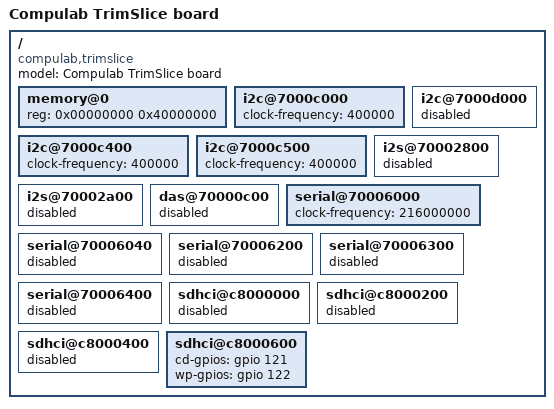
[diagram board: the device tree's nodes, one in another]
/*
 * arch/arm/boot/dts/tegra20-trimslice.dts
 *
 * Copyright (C) 2012-2014 NVIDIA Corporation. All rights reserved.
 *
 * This software is licensed under the terms of the GNU General Public
 * License version 2, as published by the Free Software Foundation, and
 * may be copied, distributed, and modified under those terms.
 *
 * This program is distributed in the hope that it will be useful,
 * but WITHOUT ANY WARRANTY; without even the implied warranty of
 * MERCHANTABILITY or FITNESS FOR A PARTICULAR PURPOSE.  See the
 * GNU General Public License for more details.
 *
 */

/dts-v1/;

/include/ "tegra20.dtsi"

/ {
	model = "Compulab TrimSlice board";
	compatible = "compulab,trimslice", "nvidia,tegra20";

	memory@0 {
		reg = < 0x00000000 0x40000000 >;
	};

	i2c@7000c000 {
		clock-frequency = <400000>;
	};

	i2c@7000c400 {
		clock-frequency = <400000>;
	};

	i2c@7000c500 {
		clock-frequency = <400000>;
	};

	i2c@7000d000 {
		status = "disable";
	};

	i2s@70002800 {
		status = "disable";
	};

	i2s@70002a00 {
		status = "disable";
	};

	das@70000c00 {
		status = "disable";
	};

	serial@70006000 {
		clock-frequency = < 216000000 >;
	};

	serial@70006040 {
		status = "disable";
	};

	serial@70006200 {
		status = "disable";
	};

	serial@70006300 {
		status = "disable";
	};

	serial@70006400 {
		status = "disable";
	};

	sdhci@c8000000 {
		status = "disable";
	};

	sdhci@c8000200 {
		status = "disable";
	};

	sdhci@c8000400 {
		status = "disable";
	};

	sdhci@c8000600 {
		cd-gpios = <&gpio 121 0>;
		wp-gpios = <&gpio 122 0>;
	};
};
